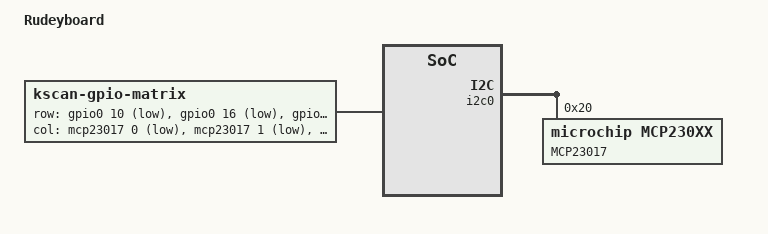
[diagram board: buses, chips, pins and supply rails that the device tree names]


&i2c0 {
    status = "okay";

    mcp23017: mcp23017@20 {
        compatible = "microchip,mcp230xx";
        status = "okay";
        gpio-controller;
        wakeup-source;
        reg = <0x20>;
        #gpio-cells = <2>;
        ngpios = <16>;
        label = "MCP23017";
    };
};


/ {
    model = "Rudeyboard";

    chosen {
        zmk,kscan = &kscan0;
    };

    kscan0: kscan {
        compatible = "zmk,kscan-gpio-matrix";
        label = "KSCAN";
        diode-direction = "col2row";


        row-gpios = <&gpio0 10 GPIO_ACTIVE_LOW>,
                    <&gpio0 16 GPIO_ACTIVE_LOW>,
                    <&gpio0 14 GPIO_ACTIVE_LOW>,
                    <&gpio0 15   GPIO_ACTIVE_LOW>,
                    <&gpio0 18 GPIO_ACTIVE_LOW>,
                    <&gpio0 19 GPIO_ACTIVE_LOW>;

        col-gpios = <&mcp23017 0 GPIO_ACTIVE_LOW>,
                    <&mcp23017 1 GPIO_ACTIVE_LOW>,
                    <&mcp23017 2 GPIO_ACTIVE_LOW>,
                    <&mcp23017 3 GPIO_ACTIVE_LOW>,
                    <&mcp23017 4 GPIO_ACTIVE_LOW>,
                    <&mcp23017 5 GPIO_ACTIVE_LOW>,
                    <&mcp23017 6 GPIO_ACTIVE_LOW>,
                    <&mcp23017 7 GPIO_ACTIVE_LOW>,
                    <&mcp23017 8 GPIO_ACTIVE_LOW>,
                    <&mcp23017 9 GPIO_ACTIVE_LOW>,
                    <&mcp23017 10 GPIO_ACTIVE_LOW>,
                    <&mcp23017 11 GPIO_ACTIVE_LOW>,
                    <&mcp23017 12 GPIO_ACTIVE_LOW>,
                    <&mcp23017 13 GPIO_ACTIVE_LOW>,
                    <&mcp23017 14 GPIO_ACTIVE_LOW>;
    };
};
